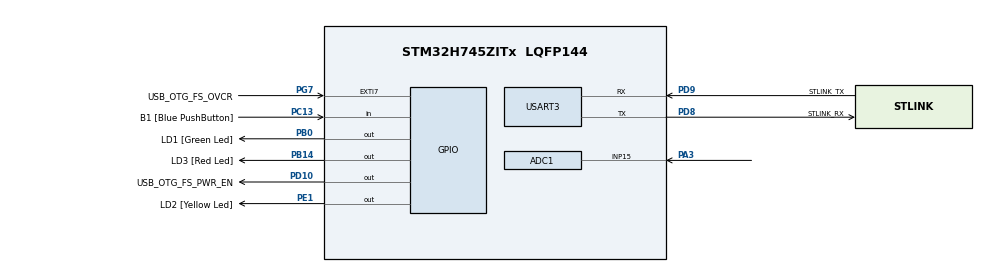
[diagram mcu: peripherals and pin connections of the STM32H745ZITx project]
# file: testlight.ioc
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ADC1.Channel-0\#ChannelRegularConversion=ADC_CHANNEL_15
ADC1.NbrOfConversionFlag=1
ADC1.OffsetNumber-0\#ChannelRegularConversion=ADC_OFFSET_NONE
ADC1.OffsetSignedSaturation-0\#ChannelRegularConversion=DISABLE
ADC1.Rank-0\#ChannelRegularConversion=1
ADC1.Resolution=ADC_RESOLUTION_10B
ADC1.SamplingTime-0\#ChannelRegularConversion=ADC_SAMPLETIME_1CYCLE_5
ADC1.master=1
CortexM4.IPs=FATFS_M4\:I,FREERTOS_M4\:I,IWDG2\:I,RCC,WWDG2\:I,DMA,BDMA,MDMA,NVIC2\:I,ETH,DEBUG,PDM2PCM_M4\:I,PWR,RESMGR_UTILITY,SYS_M4\:I,USB_DEVICE_M4\:I,USB_HOST_M4\:I,CORTEX_M4\:I,OPENAMP_M4\:I,VREFBUF
CortexM7.IPs=FATFS_M7\:I,FREERTOS_M7\:I,IWDG1\:I,RCC\:I,WWDG1\:I,DMA\:I,BDMA\:I,MDMA\:I,NVIC1\:I,SYS\:I,USART3\:I,USB_OTG_FS\:I,ETH\:I,CORTEX_M7\:I,DEBUG\:I,PDM2PCM_M7\:I,PWR\:I,RESMGR_UTILITY\:I,USB_DEVICE_M7\:I,USB_HOST_M7\:I,OPENAMP_M7\:I,VREFBUF\:I,ADC1\:I
CortexM7.Pins=PE1
Mcu.Family=STM32H7
Mcu.Name=STM32H745ZITx
Mcu.Package=LQFP144
NVIC1.PriorityGroup=NVIC_PRIORITYGROUP_4
NVIC2.PriorityGroup=NVIC_PRIORITYGROUP_4
PA1.PinAttribute=CortexM7
PA1.Signal=ETH_REF_CLK
PA11.PinAttribute=CortexM7
PA11.Signal=USB_OTG_FS_DM
PA12.PinAttribute=CortexM7
PA12.Signal=USB_OTG_FS_DP
PA2.PinAttribute=CortexM7
PA2.Signal=ETH_MDIO
PA3.PinAttribute=CortexM7
PA3.Signal=SharedAnalog_PA3
PA7.PinAttribute=CortexM7
PA7.Signal=ETH_CRS_DV
PA8.PinAttribute=CortexM7
PA8.Signal=USB_OTG_FS_SOF
PA9.PinAttribute=CortexM7
PA9.Signal=USB_OTG_FS_VBUS
PB0.GPIO_Label=LD1 [Green Led]
PB0.PinAttribute=Free
PB0.Signal=GPIO_Output
PB13.PinAttribute=CortexM7
PB13.Signal=ETH_TXD1
PB14.GPIO_Label=LD3 [Red Led]
PB14.PinAttribute=Free
PB14.Signal=GPIO_Output
PC1.PinAttribute=CortexM7
PC1.Signal=ETH_MDC
PC13.GPIO_Label=B1 [Blue PushButton]
PC13.PinAttribute=Free
PC13.Signal=GPIO_Input
PC14-OSC32_IN\ (OSC32_IN).PinAttribute=CortexM7
PC14-OSC32_IN\ (OSC32_IN).Signal=RCC_OSC32_IN
PC15-OSC32_OUT\ (OSC32_OUT).PinAttribute=CortexM7
PC15-OSC32_OUT\ (OSC32_OUT).Signal=RCC_OSC32_OUT
PC4.PinAttribute=CortexM7
PC4.Signal=ETH_RXD0
PC5.PinAttribute=CortexM7
PC5.Signal=ETH_RXD1
PD10.GPIO_Label=USB_OTG_FS_PWR_EN
PD10.PinAttribute=Free
PD10.Signal=GPIO_Output
PD8.GPIO_Label=STLINK_RX
PD8.Mode=Asynchronous
PD8.PinAttribute=CortexM7
PD8.Signal=USART3_TX
PD9.GPIO_Label=STLINK_TX
PD9.Mode=Asynchronous
PD9.PinAttribute=CortexM7
PD9.Signal=USART3_RX
PE1.GPIO_Label=LD2 [Yellow Led]
PE1.PinAttribute=CortexM7
PE1.Signal=GPIO_Output
PG11.PinAttribute=CortexM7
PG11.Signal=ETH_TX_EN
PG13.PinAttribute=CortexM7
PG13.Signal=ETH_TXD0
PG7.GPIO_Label=USB_OTG_FS_OVCR
PG7.PinAttribute=Free
PG7.Signal=GPXTI7
PH0-OSC_IN\ (PH0).PinAttribute=CortexM7
PH0-OSC_IN\ (PH0).Signal=RCC_OSC_IN
PH1-OSC_OUT\ (PH1).PinAttribute=CortexM7
PH1-OSC_OUT\ (PH1).Signal=RCC_OSC_OUT
ProjectManager.HeapSize=0x200
ProjectManager.StackSize=0x400
ProjectManager.TargetToolchain=STM32CubeIDE
RCC.ADCFreq_Value=129000000
RCC.APB1Freq_Value=64000000
RCC.APB2Freq_Value=64000000
RCC.APB3Freq_Value=64000000
RCC.APB4Freq_Value=64000000
RCC.CortexFreq_Value=64000000
RCC.DIVM1=18
RCC.DIVM3=22
RCC.DIVN3=169
RCC.DIVQ3=4
RCC.HCLKFreq_Value=64000000
RCC.PLL2FRACN=0
RCC.PLL3FRACN=0
RCC.PLLFRACN=0
RCC.SYSCLKFreq_VALUE=64000000
RCC.SupplySource=PWR_DIRECT_SMPS_SUPPLY
RCC.USBCLockSelection=RCC_USBCLKSOURCE_PLL3
RCC.USBFreq_Value=122909090.9090909
SH.SharedAnalog_PA3.0=GPIO_Analog
SH.SharedAnalog_PA3.1=ADC1_INP15,IN15-Single-Ended
USART3.VirtualMode-Asynchronous=VM_ASYNC
VP_SYS_M4_VS_Systick.Mode=SysTick
board=NUCLEO-H745ZI-Q

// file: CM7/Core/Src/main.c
/* USER CODE BEGIN Header */
/**
  ******************************************************************************
  * @file           : main.c
  * @brief          : Main program body
  ******************************************************************************
  * @attention
  *
  * <h2><center>&copy; Copyright (c) 2021 STMicroelectronics.
  * All rights reserved.</center></h2>
  *
  * This software component is licensed by ST under BSD 3-Clause license,
  * the "License"; You may not use this file except in compliance with the
  * License. You may obtain a copy of the License at:
  *                        opensource.org/licenses/BSD-3-Clause
  *
  ******************************************************************************
  */
/* USER CODE END Header */
#include "main.h"

/* USER CODE BEGIN PD */

#ifndef HSEM_ID_0
#define HSEM_ID_0 (0U) /* HW semaphore 0*/
#endif
/* USER CODE END PD */

ADC_HandleTypeDef hadc1;

UART_HandleTypeDef huart3;

void SystemClock_Config(void);
static void MX_GPIO_Init(void);
static void MX_ADC1_Init(void);
static void MX_USART3_UART_Init(void);

int main(void)
{
/* USER CODE BEGIN Boot_Mode_Sequence_0 */
  int32_t timeout;
/* USER CODE END Boot_Mode_Sequence_0 */

/* USER CODE BEGIN Boot_Mode_Sequence_1 */
  /* Wait until CPU2 boots and enters in stop mode or timeout*/
  timeout = 0xFFFF;
  while((__HAL_RCC_GET_FLAG(RCC_FLAG_D2CKRDY) != RESET) && (timeout-- > 0));
  if ( timeout < 0 )
  {
  Error_Handler();
  }
/* USER CODE END Boot_Mode_Sequence_1 */
  /* MCU Configuration--------------------------------------------------------*/

  /* Reset of all peripherals, Initializes the Flash interface and the Systick. */
  HAL_Init();

  /* Configure the system clock */
  SystemClock_Config();
/* USER CODE BEGIN Boot_Mode_Sequence_2 */
/* When system initialization is finished, Cortex-M7 will release Cortex-M4 by means of
HSEM notification */
/*HW semaphore Clock enable*/
__HAL_RCC_HSEM_CLK_ENABLE();
/*Take HSEM */
HAL_HSEM_FastTake(HSEM_ID_0);
/*Release HSEM in order to notify the CPU2(CM4)*/
HAL_HSEM_Release(HSEM_ID_0,0);
/* wait until CPU2 wakes up from stop mode */
timeout = 0xFFFF;
while((__HAL_RCC_GET_FLAG(RCC_FLAG_D2CKRDY) == RESET) && (timeout-- > 0));
if ( timeout < 0 )
{
Error_Handler();
}
/* USER CODE END Boot_Mode_Sequence_2 */

  /* Initialize all configured peripherals */
  MX_GPIO_Init();
  MX_ADC1_Init();
  MX_USART3_UART_Init();

  /* Infinite loop */
  /* USER CODE BEGIN WHILE */
  uint32_t a_val;
     float meas;
     char speech_vol[100];
     char speech_analog_val[100];
     int speech_len;
  while (1)
  {
    /* USER CODE END WHILE */
	  HAL_ADC_Start(&hadc1);
	          HAL_ADC_PollForConversion(&hadc1, HAL_MAX_DELAY);
	          a_val = HAL_ADC_GetValue(&hadc1);
	          meas = (float)a_val / (1024 - 1) * 3.3;
	          if (meas < (float)0.9)
	              HAL_GPIO_WritePin(GPIOE, GPIO_PIN_1, GPIO_PIN_SET);
	          else
	              HAL_GPIO_WritePin(GPIOE, GPIO_PIN_1, GPIO_PIN_RESET);
	          speech_len = sprintf(speech_vol, "Vol_V = %.2f\r\n", meas);
	          HAL_UART_Transmit(&huart3, speech_vol, speech_len, HAL_MAX_DELAY);
	          speech_len = sprintf(speech_analog_val, "Analog_Val = %d\r\n", a_val);
	          HAL_UART_Transmit(&huart3, speech_analog_val, speech_len, HAL_MAX_DELAY);

	          HAL_Delay(500);
  }
}

void SystemClock_Config(void)
{
  RCC_OscInitTypeDef RCC_OscInitStruct = {0};
  RCC_ClkInitTypeDef RCC_ClkInitStruct = {0};
  RCC_PeriphCLKInitTypeDef PeriphClkInitStruct = {0};

  /** Supply configuration update enable
  */
  HAL_PWREx_ConfigSupply(PWR_DIRECT_SMPS_SUPPLY);
  /** Configure the main internal regulator output voltage
  */
  __HAL_PWR_VOLTAGESCALING_CONFIG(PWR_REGULATOR_VOLTAGE_SCALE3);

  while(!__HAL_PWR_GET_FLAG(PWR_FLAG_VOSRDY)) {}
  /** Macro to configure the PLL clock source
  */
  __HAL_RCC_PLL_PLLSOURCE_CONFIG(RCC_PLLSOURCE_HSI);
  /** Initializes the RCC Oscillators according to the specified parameters
  * in the RCC_OscInitTypeDef structure.
  */
  RCC_OscInitStruct.OscillatorType = RCC_OSCILLATORTYPE_HSI;
  RCC_OscInitStruct.HSIState = RCC_HSI_DIV1;
  RCC_OscInitStruct.HSICalibrationValue = RCC_HSICALIBRATION_DEFAULT;
  RCC_OscInitStruct.PLL.PLLState = RCC_PLL_NONE;
  RCC_OscInitStruct.PLL.PLLSource = RCC_PLLSOURCE_HSI;
  if (HAL_RCC_OscConfig(&RCC_OscInitStruct) != HAL_OK)
  {
    Error_Handler();
  }
  /** Initializes the CPU, AHB and APB buses clocks
  */
  RCC_ClkInitStruct.ClockType = RCC_CLOCKTYPE_HCLK|RCC_CLOCKTYPE_SYSCLK
                              |RCC_CLOCKTYPE_PCLK1|RCC_CLOCKTYPE_PCLK2
                              |RCC_CLOCKTYPE_D3PCLK1|RCC_CLOCKTYPE_D1PCLK1;
  RCC_ClkInitStruct.SYSCLKSource = RCC_SYSCLKSOURCE_HSI;
  RCC_ClkInitStruct.SYSCLKDivider = RCC_SYSCLK_DIV1;
  RCC_ClkInitStruct.AHBCLKDivider = RCC_HCLK_DIV1;
  RCC_ClkInitStruct.APB3CLKDivider = RCC_APB3_DIV1;
  RCC_ClkInitStruct.APB1CLKDivider = RCC_APB1_DIV1;
  RCC_ClkInitStruct.APB2CLKDivider = RCC_APB2_DIV1;
  RCC_ClkInitStruct.APB4CLKDivider = RCC_APB4_DIV1;

  if (HAL_RCC_ClockConfig(&RCC_ClkInitStruct, FLASH_LATENCY_0) != HAL_OK)
  {
    Error_Handler();
  }
  PeriphClkInitStruct.PeriphClockSelection = RCC_PERIPHCLK_USART3|RCC_PERIPHCLK_ADC;
  PeriphClkInitStruct.PLL2.PLL2M = 32;
  PeriphClkInitStruct.PLL2.PLL2N = 129;
  PeriphClkInitStruct.PLL2.PLL2P = 2;
  PeriphClkInitStruct.PLL2.PLL2Q = 2;
  PeriphClkInitStruct.PLL2.PLL2R = 2;
  PeriphClkInitStruct.PLL2.PLL2RGE = RCC_PLL2VCIRANGE_1;
  PeriphClkInitStruct.PLL2.PLL2VCOSEL = RCC_PLL2VCOWIDE;
  PeriphClkInitStruct.PLL2.PLL2FRACN = 0;
  PeriphClkInitStruct.Usart234578ClockSelection = RCC_USART234578CLKSOURCE_D2PCLK1;
  PeriphClkInitStruct.AdcClockSelection = RCC_ADCCLKSOURCE_PLL2;
  if (HAL_RCCEx_PeriphCLKConfig(&PeriphClkInitStruct) != HAL_OK)
  {
    Error_Handler();
  }
}

static void MX_ADC1_Init(void)
{

  ADC_MultiModeTypeDef multimode = {0};
  ADC_ChannelConfTypeDef sConfig = {0};

  /** Common config
  */
  hadc1.Instance = ADC1;
  hadc1.Init.ClockPrescaler = ADC_CLOCK_ASYNC_DIV1;
  hadc1.Init.Resolution = ADC_RESOLUTION_10B;
  hadc1.Init.ScanConvMode = ADC_SCAN_DISABLE;
  hadc1.Init.EOCSelection = ADC_EOC_SINGLE_CONV;
  hadc1.Init.LowPowerAutoWait = DISABLE;
  hadc1.Init.ContinuousConvMode = DISABLE;
  hadc1.Init.NbrOfConversion = 1;
  hadc1.Init.DiscontinuousConvMode = DISABLE;
  hadc1.Init.ExternalTrigConv = ADC_SOFTWARE_START;
  hadc1.Init.ExternalTrigConvEdge = ADC_EXTERNALTRIGCONVEDGE_NONE;
  hadc1.Init.ConversionDataManagement = ADC_CONVERSIONDATA_DR;
  hadc1.Init.Overrun = ADC_OVR_DATA_PRESERVED;
  hadc1.Init.LeftBitShift = ADC_LEFTBITSHIFT_NONE;
  hadc1.Init.OversamplingMode = DISABLE;
  if (HAL_ADC_Init(&hadc1) != HAL_OK)
  {
    Error_Handler();
  }
  /** Configure the ADC multi-mode
  */
  multimode.Mode = ADC_MODE_INDEPENDENT;
  if (HAL_ADCEx_MultiModeConfigChannel(&hadc1, &multimode) != HAL_OK)
  {
    Error_Handler();
  }
  /** Configure Regular Channel
  */
  sConfig.Channel = ADC_CHANNEL_15;
  sConfig.Rank = ADC_REGULAR_RANK_1;
  sConfig.SamplingTime = ADC_SAMPLETIME_1CYCLE_5;
  sConfig.SingleDiff = ADC_SINGLE_ENDED;
  sConfig.OffsetNumber = ADC_OFFSET_NONE;
  sConfig.Offset = 0;
  sConfig.OffsetSignedSaturation = DISABLE;
  if (HAL_ADC_ConfigChannel(&hadc1, &sConfig) != HAL_OK)
  {
    Error_Handler();
  }

}

static void MX_USART3_UART_Init(void)
{

  huart3.Instance = USART3;
  huart3.Init.BaudRate = 115200;
  huart3.Init.WordLength = UART_WORDLENGTH_8B;
  huart3.Init.StopBits = UART_STOPBITS_1;
  huart3.Init.Parity = UART_PARITY_NONE;
  huart3.Init.Mode = UART_MODE_TX_RX;
  huart3.Init.HwFlowCtl = UART_HWCONTROL_NONE;
  huart3.Init.OverSampling = UART_OVERSAMPLING_16;
  huart3.Init.OneBitSampling = UART_ONE_BIT_SAMPLE_DISABLE;
  huart3.Init.ClockPrescaler = UART_PRESCALER_DIV1;
  huart3.AdvancedInit.AdvFeatureInit = UART_ADVFEATURE_NO_INIT;
  if (HAL_UART_Init(&huart3) != HAL_OK)
  {
    Error_Handler();
  }
  if (HAL_UARTEx_SetTxFifoThreshold(&huart3, UART_TXFIFO_THRESHOLD_1_8) != HAL_OK)
  {
    Error_Handler();
  }
  if (HAL_UARTEx_SetRxFifoThreshold(&huart3, UART_RXFIFO_THRESHOLD_1_8) != HAL_OK)
  {
    Error_Handler();
  }
  if (HAL_UARTEx_DisableFifoMode(&huart3) != HAL_OK)
  {
    Error_Handler();
  }

}

static void MX_GPIO_Init(void)
{
  GPIO_InitTypeDef GPIO_InitStruct = {0};

  /* GPIO Ports Clock Enable */
  __HAL_RCC_GPIOC_CLK_ENABLE();
  __HAL_RCC_GPIOH_CLK_ENABLE();
  __HAL_RCC_GPIOA_CLK_ENABLE();
  __HAL_RCC_GPIOB_CLK_ENABLE();
  __HAL_RCC_GPIOD_CLK_ENABLE();
  __HAL_RCC_GPIOG_CLK_ENABLE();
  __HAL_RCC_GPIOE_CLK_ENABLE();

  /*Configure GPIO pin Output Level */
  HAL_GPIO_WritePin(LD2_GPIO_Port, LD2_Pin, GPIO_PIN_RESET);

  /*Configure GPIO pins : PC1 PC4 PC5 */
  GPIO_InitStruct.Pin = GPIO_PIN_1|GPIO_PIN_4|GPIO_PIN_5;
  GPIO_InitStruct.Mode = GPIO_MODE_AF_PP;
  GPIO_InitStruct.Pull = GPIO_NOPULL;
  GPIO_InitStruct.Speed = GPIO_SPEED_FREQ_LOW;
  GPIO_InitStruct.Alternate = GPIO_AF11_ETH;
  HAL_GPIO_Init(GPIOC, &GPIO_InitStruct);

  /*Configure GPIO pins : PA1 PA2 PA7 */
  GPIO_InitStruct.Pin = GPIO_PIN_1|GPIO_PIN_2|GPIO_PIN_7;
  GPIO_InitStruct.Mode = GPIO_MODE_AF_PP;
  GPIO_InitStruct.Pull = GPIO_NOPULL;
  GPIO_InitStruct.Speed = GPIO_SPEED_FREQ_LOW;
  GPIO_InitStruct.Alternate = GPIO_AF11_ETH;
  HAL_GPIO_Init(GPIOA, &GPIO_InitStruct);

  /*Configure GPIO pin : PB13 */
  GPIO_InitStruct.Pin = GPIO_PIN_13;
  GPIO_InitStruct.Mode = GPIO_MODE_AF_PP;
  GPIO_InitStruct.Pull = GPIO_NOPULL;
  GPIO_InitStruct.Speed = GPIO_SPEED_FREQ_LOW;
  GPIO_InitStruct.Alternate = GPIO_AF11_ETH;
  HAL_GPIO_Init(GPIOB, &GPIO_InitStruct);

  /*Configure GPIO pins : PA8 PA11 PA12 */
  GPIO_InitStruct.Pin = GPIO_PIN_8|GPIO_PIN_11|GPIO_PIN_12;
  GPIO_InitStruct.Mode = GPIO_MODE_AF_PP;
  GPIO_InitStruct.Pull = GPIO_NOPULL;
  GPIO_InitStruct.Speed = GPIO_SPEED_FREQ_LOW;
  GPIO_InitStruct.Alternate = GPIO_AF10_OTG1_FS;
  HAL_GPIO_Init(GPIOA, &GPIO_InitStruct);

  /*Configure GPIO pins : PG11 PG13 */
  GPIO_InitStruct.Pin = GPIO_PIN_11|GPIO_PIN_13;
  GPIO_InitStruct.Mode = GPIO_MODE_AF_PP;
  GPIO_InitStruct.Pull = GPIO_NOPULL;
  GPIO_InitStruct.Speed = GPIO_SPEED_FREQ_LOW;
  GPIO_InitStruct.Alternate = GPIO_AF11_ETH;
  HAL_GPIO_Init(GPIOG, &GPIO_InitStruct);

  /*Configure GPIO pin : LD2_Pin */
  GPIO_InitStruct.Pin = LD2_Pin;
  GPIO_InitStruct.Mode = GPIO_MODE_OUTPUT_PP;
  GPIO_InitStruct.Pull = GPIO_NOPULL;
  GPIO_InitStruct.Speed = GPIO_SPEED_FREQ_LOW;
  HAL_GPIO_Init(LD2_GPIO_Port, &GPIO_InitStruct);

}

void Error_Handler(void)
{
  __disable_irq();
  while (1)
  {
  }
}

/************************ (C) COPYRIGHT STMicroelectronics *****END OF FILE****/
